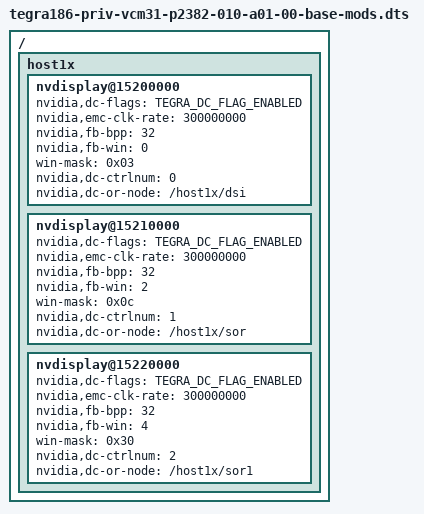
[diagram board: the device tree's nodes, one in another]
/*
 * tegra186-priv-vcm31-p2382-010-a01-00-base-mods.dts: 62382 MODS DTS
 * file
 *
 * Copyright (c) 2016, NVIDIA CORPORATION.  All rights reserved.
 *
 * This program is free software; you can redistribute it and/or modify
 * it under the terms of the GNU General Public License as published by
 * the Free Software Foundation; version 2 of the License.
 *
 * This program is distributed in the hope that it will be useful, but WITHOUT
 * ANY WARRANTY; without even the implied warranty of MERCHANTABILITY or
 * FITNESS FOR A PARTICULAR PURPOSE.  See the GNU General Public License for
 * more details.
 */

#include "tegra186-priv-vcm31-p2382-010-a01-00-base.dts"

/* All MODS overrides below */

/ {
	host1x {
		status = "okay";

		nvdisplay@15200000 {
			status = "okay";
			nvidia,dc-flags = <TEGRA_DC_FLAG_ENABLED>;
			nvidia,emc-clk-rate = <300000000>;
			nvidia,fb-bpp = <32>; /* bits per pixel */
			nvidia,fb-win = <0>;
			win-mask = <0x03>;
			nvidia,dc-ctrlnum = <0>;
			nvidia,dc-or-node = "/host1x/dsi";
		};

		nvdisplay@15210000 {
			status = "okay";
			nvidia,dc-flags = <TEGRA_DC_FLAG_ENABLED>;
			nvidia,emc-clk-rate = <300000000>;
			nvidia,fb-bpp = <32>; /* bits per pixel */
			nvidia,fb-win = <2>;
			win-mask = <0x0c>;
			nvidia,dc-ctrlnum = <1>;
			nvidia,dc-or-node = "/host1x/sor";
		};

		nvdisplay@15220000 {
			status = "okay";
			nvidia,dc-flags = <TEGRA_DC_FLAG_ENABLED>;
			nvidia,emc-clk-rate = <300000000>;
			nvidia,fb-bpp = <32>; /* bits per pixel */
			nvidia,fb-win = <4>;
			win-mask = <0x30>;
			nvidia,dc-ctrlnum = <2>;
			nvidia,dc-or-node = "/host1x/sor1";
		};
	};
};
